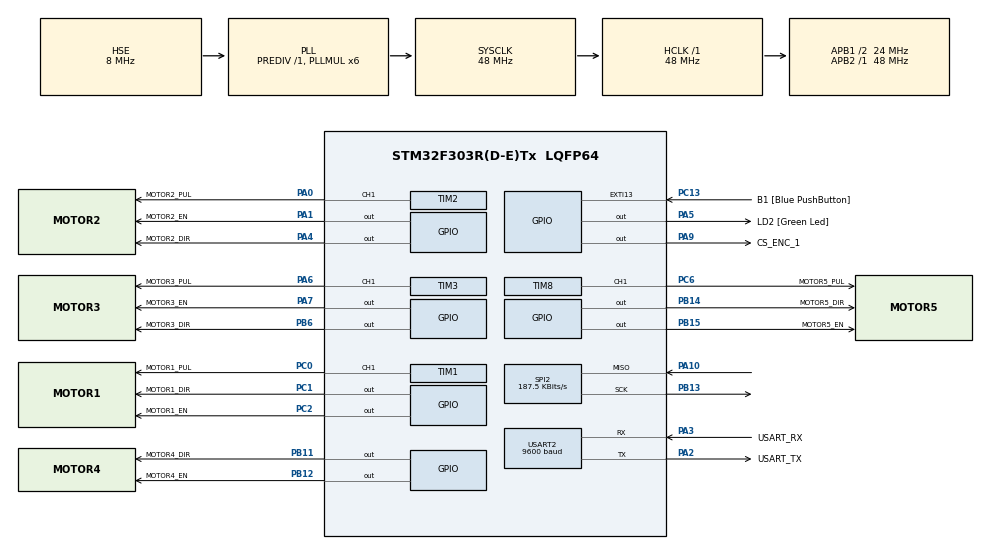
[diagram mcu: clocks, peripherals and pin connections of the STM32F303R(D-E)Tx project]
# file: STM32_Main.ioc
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Mcu.Family=STM32F3
Mcu.Name=STM32F303R(D-E)Tx
Mcu.Package=LQFP64
NVIC.PriorityGroup=NVIC_PRIORITYGROUP_0
NVIC.TIM1_CC_IRQn=true\:0\:0\:false\:false\:true\:true\:true\:true
NVIC.TIM2_IRQn=true\:0\:0\:false\:false\:true\:true\:true\:true
NVIC.USART2_IRQn=true\:0\:0\:false\:false\:true\:true\:true\:true
PA0.GPIO_Label=MOTOR2_PUL
PA0.Signal=S_TIM2_CH1_ETR
PA1.GPIO_Label=MOTOR2_EN
PA1.Signal=GPIO_Output
PA10.Mode=RX_Only_Simplex_Unidirect_Master
PA10.Signal=SPI2_MISO
PA14.GPIO_Label=TCK
PA14.Signal=SYS_JTCK-SWCLK
PA2.GPIO_Label=USART_TX
PA2.GPIO_Mode=GPIO_MODE_AF_PP
PA2.GPIO_PuPd=GPIO_NOPULL
PA2.GPIO_Speed=GPIO_SPEED_FREQ_LOW
PA2.Mode=Asynchronous
PA2.Signal=USART2_TX
PA3.GPIO_Label=USART_RX
PA3.GPIO_Mode=GPIO_MODE_AF_PP
PA3.GPIO_PuPd=GPIO_NOPULL
PA3.GPIO_Speed=GPIO_SPEED_FREQ_LOW
PA3.Mode=Asynchronous
PA3.Signal=USART2_RX
PA4.GPIO_Label=MOTOR2_DIR
PA4.Signal=GPIO_Output
PA5.GPIO_Label=LD2 [Green Led]
PA5.GPIO_PuPd=GPIO_NOPULL
PA5.GPIO_Speed=GPIO_SPEED_FREQ_LOW
PA5.Signal=GPIO_Output
PA6.GPIO_Label=MOTOR3_PUL
PA6.Signal=S_TIM3_CH1
PA7.GPIO_Label=MOTOR3_EN
PA7.Signal=GPIO_Output
PA9.GPIO_Label=CS_ENC_1
PA9.Signal=GPIO_Output
PB11.GPIO_Label=MOTOR4_DIR
PB11.Signal=GPIO_Output
PB12.GPIO_Label=MOTOR4_EN
PB12.Signal=GPIO_Output
PB13.Mode=RX_Only_Simplex_Unidirect_Master
PB13.Signal=SPI2_SCK
PB14.GPIO_Label=MOTOR5_DIR
PB14.Signal=GPIO_Output
PB15.GPIO_Label=MOTOR5_EN
PB15.Signal=GPIO_Output
PB3.GPIO_Label=SWO
PB3.Signal=SYS_JTDO-TRACESWO
PB6.GPIO_Label=MOTOR3_DIR
PB6.Signal=GPIO_Output
PC0.GPIO_Label=MOTOR1_PUL
PC0.Signal=S_TIM1_CH1
PC1.GPIO_Label=MOTOR1_DIR
PC1.Signal=GPIO_Output
PC13.GPIO_Label=B1 [Blue PushButton]
PC13.GPIO_ModeDefaultEXTI=GPIO_MODE_IT_FALLING
PC13.Signal=GPXTI13
PC14-OSC32_IN.Mode=LSE-External-Oscillator
PC14-OSC32_IN.Signal=RCC_OSC32_IN
PC15-OSC32_OUT.Mode=LSE-External-Oscillator
PC15-OSC32_OUT.Signal=RCC_OSC32_OUT
PC2.GPIO_Label=MOTOR1_EN
PC2.Signal=GPIO_Output
PC6.GPIO_Label=MOTOR5_PUL
PC6.Signal=S_TIM8_CH1
PF0-OSC_IN.Mode=HSE-External-Clock-Source
PF0-OSC_IN.Signal=RCC_OSC_IN
PF1-OSC_OUT.Signal=RCC_OSC_OUT
ProjectManager.HeapSize=0x200
ProjectManager.StackSize=0x400
ProjectManager.TargetToolchain=STM32CubeIDE
RCC.AHBFreq_Value=48000000
RCC.APB1CLKDivider=RCC_HCLK_DIV2
RCC.APB1Freq_Value=24000000
RCC.APB1TimFreq_Value=48000000
RCC.APB2Freq_Value=48000000
RCC.APB2TimFreq_Value=48000000
RCC.CortexFreq_Value=48000000
RCC.HCLKFreq_Value=48000000
RCC.HSE_VALUE=8000000
RCC.HSI_VALUE=8000000
RCC.PLLM=8
RCC.PLLMUL=RCC_PLL_MUL6
RCC.PLLN=336
RCC.PLLP=RCC_PLLP_DIV4
RCC.PLLQ=7
RCC.PLLSourceVirtual=RCC_PLLSOURCE_HSE
RCC.RCC_PLLsource_Clock_Source_FROM_HSE=RCC_HSE_PREDIV_DIV2
RCC.SYSCLKFreq_VALUE=48000000
RCC.SYSCLKSourceVirtual=RCC_SYSCLKSOURCE_PLLCLK
RCC.USBFreq_Value=48000000
SH.S_TIM1_CH1.0=TIM1_CH1,PWM Generation1 CH1
SH.S_TIM2_CH1_ETR.0=TIM2_CH1,PWM Generation1 CH1
SH.S_TIM3_CH1.0=TIM3_CH1,PWM Generation1 CH1
SH.S_TIM8_CH1.0=TIM8_CH1,PWM Generation1 CH1
SPI2.BaudRatePrescaler=SPI_BAUDRATEPRESCALER_128
SPI2.CLKPolarity=SPI_POLARITY_HIGH
SPI2.CalculateBaudRate=187.5 KBits/s
SPI2.DataSize=SPI_DATASIZE_8BIT
SPI2.Direction=SPI_DIRECTION_2LINES_RXONLY
SPI2.Mode=SPI_MODE_MASTER
SPI2.VirtualType=VM_MASTER
TIM1.AutoReloadPreload=TIM_AUTORELOAD_PRELOAD_ENABLE
TIM1.Channel-PWM\ Generation1\ CH1=TIM_CHANNEL_1
TIM1.OCIdleState_1=TIM_OCIDLESTATE_SET
TIM1.OCPolarity_1=TIM_OCPOLARITY_LOW
TIM1.Period=150
TIM1.Prescaler=4
TIM1.Pulse-PWM\ Generation1\ CH1=75
TIM2.AutoReloadPreload=TIM_AUTORELOAD_PRELOAD_ENABLE
TIM2.Channel-PWM\ Generation1\ CH1=TIM_CHANNEL_1
TIM2.Period=150
TIM2.Prescaler=0
TIM2.Pulse-PWM\ Generation1\ CH1=75
TIM3.AutoReloadPreload=TIM_AUTORELOAD_PRELOAD_ENABLE
TIM3.Channel-PWM\ Generation1\ CH1=TIM_CHANNEL_1
TIM3.Period=150
TIM3.Prescaler=0
TIM3.Pulse-PWM\ Generation1\ CH1=75
TIM4.AutoReloadPreload=TIM_AUTORELOAD_PRELOAD_ENABLE
TIM4.Period=150
TIM4.Prescaler=0
TIM8.AutoReloadPreload=TIM_AUTORELOAD_PRELOAD_ENABLE
TIM8.Channel-PWM\ Generation1\ CH1=TIM_CHANNEL_1
TIM8.Period=150
TIM8.Prescaler=0
TIM8.Pulse-PWM\ Generation1\ CH1=75
USART2.BaudRate=9600
USART2.VirtualMode-Asynchronous=VM_ASYNC
VP_TIM1_VS_ClockSourceINT.Mode=Internal
VP_TIM2_VS_ClockSourceINT.Mode=Internal
VP_TIM3_VS_ClockSourceINT.Mode=Internal
VP_TIM4_VS_ClockSourceINT.Mode=Internal
VP_TIM8_VS_ClockSourceINT.Mode=Internal
board=NUCLEO-F303RE

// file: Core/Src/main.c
/* USER CODE BEGIN Header */
/**
  ******************************************************************************
  * @file           : main.c
  * @brief          : Main program body
  ******************************************************************************
  * @attention
  *
  * Copyright (c) 2024 STMicroelectronics.
  * All rights reserved.
  *
  * This software is licensed under terms that can be found in the LICENSE file
  * in the root directory of this software component.
  * If no LICENSE file comes with this software, it is provided AS-IS.
  *
  ******************************************************************************
  */
/* USER CODE END Header */
#include "main.h"
#include "spi.h"
#include "tim.h"
#include "usart.h"
#include "gpio.h"

/* USER CODE BEGIN Includes */
#include "motors.h"
#include "variables.h"
#include <string.h>
#include <stdio.h>
#include <stdlib.h>

/* USER CODE END Includes */

void SystemClock_Config(void);

int main(void)
{

  /* MCU Configuration--------------------------------------------------------*/

  /* Reset of all peripherals, Initializes the Flash interface and the Systick. */
  HAL_Init();

  /* Configure the system clock */
  SystemClock_Config();

  /* Initialize all configured peripherals */
  MX_GPIO_Init();
  MX_USART2_UART_Init();
  MX_TIM3_Init();
  MX_TIM1_Init();
  MX_TIM2_Init();
  MX_TIM4_Init();
  MX_TIM8_Init();
  MX_SPI2_Init();
  /* USER CODE BEGIN 2 */
  SPI_init();
  USART_init();

  /* USER CODE END 2 */

  /* Infinite loop */
  while (1)
  {

    /* USER CODE BEGIN 3 */
	  /*MOTOR_main();

	  if (USART_drdy()){
		  USART_reset_drdy();
		  MOTOR_set_all(USART_get_buffer());
	  }
*/

	  //SPI_read_data(encoders.enc_1.value); //loeme info structi
	  SPI_test();
	  //HAL_UART_Transmit(&huart2, &encoders.enc_1.value, sizeof(encoders.enc_1.value), HAL_MAX_DELAY);

  }
  /* USER CODE END 3 */
}

void SystemClock_Config(void)
{
  RCC_OscInitTypeDef RCC_OscInitStruct = {0};
  RCC_ClkInitTypeDef RCC_ClkInitStruct = {0};
  RCC_PeriphCLKInitTypeDef PeriphClkInit = {0};

  /** Initializes the RCC Oscillators according to the specified parameters
  * in the RCC_OscInitTypeDef structure.
  */
  RCC_OscInitStruct.OscillatorType = RCC_OSCILLATORTYPE_HSE;
  RCC_OscInitStruct.HSEState = RCC_HSE_BYPASS;
  RCC_OscInitStruct.HSIState = RCC_HSI_ON;
  RCC_OscInitStruct.PLL.PLLState = RCC_PLL_ON;
  RCC_OscInitStruct.PLL.PLLSource = RCC_PLLSOURCE_HSE;
  RCC_OscInitStruct.PLL.PLLMUL = RCC_PLL_MUL6;
  RCC_OscInitStruct.PLL.PREDIV = RCC_PREDIV_DIV1;
  if (HAL_RCC_OscConfig(&RCC_OscInitStruct) != HAL_OK)
  {
    Error_Handler();
  }

  /** Initializes the CPU, AHB and APB buses clocks
  */
  RCC_ClkInitStruct.ClockType = RCC_CLOCKTYPE_HCLK|RCC_CLOCKTYPE_SYSCLK
                              |RCC_CLOCKTYPE_PCLK1|RCC_CLOCKTYPE_PCLK2;
  RCC_ClkInitStruct.SYSCLKSource = RCC_SYSCLKSOURCE_PLLCLK;
  RCC_ClkInitStruct.AHBCLKDivider = RCC_SYSCLK_DIV1;
  RCC_ClkInitStruct.APB1CLKDivider = RCC_HCLK_DIV2;
  RCC_ClkInitStruct.APB2CLKDivider = RCC_HCLK_DIV1;

  if (HAL_RCC_ClockConfig(&RCC_ClkInitStruct, FLASH_LATENCY_1) != HAL_OK)
  {
    Error_Handler();
  }
  PeriphClkInit.PeriphClockSelection = RCC_PERIPHCLK_USART2|RCC_PERIPHCLK_TIM1
                              |RCC_PERIPHCLK_TIM8|RCC_PERIPHCLK_TIM2
                              |RCC_PERIPHCLK_TIM34;
  PeriphClkInit.Usart2ClockSelection = RCC_USART2CLKSOURCE_PCLK1;
  PeriphClkInit.Tim1ClockSelection = RCC_TIM1CLK_HCLK;
  PeriphClkInit.Tim8ClockSelection = RCC_TIM8CLK_HCLK;
  PeriphClkInit.Tim2ClockSelection = RCC_TIM2CLK_HCLK;
  PeriphClkInit.Tim34ClockSelection = RCC_TIM34CLK_HCLK;
  if (HAL_RCCEx_PeriphCLKConfig(&PeriphClkInit) != HAL_OK)
  {
    Error_Handler();
  }
}

void Error_Handler(void)
{
  __disable_irq();
  while (1)
  {
  }
}
